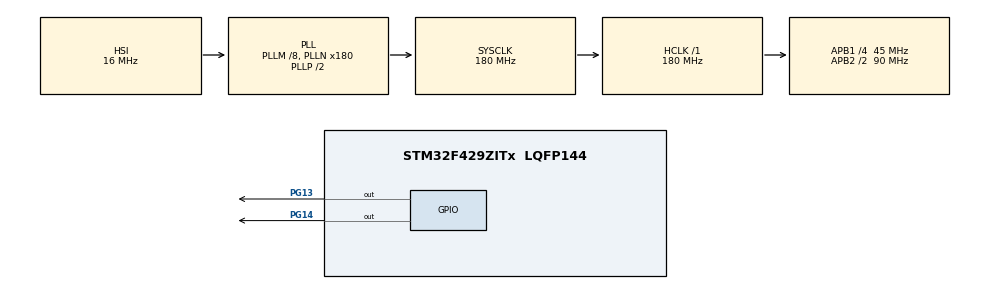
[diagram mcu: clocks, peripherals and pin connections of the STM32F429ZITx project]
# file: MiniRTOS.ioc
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Mcu.Family=STM32F4
Mcu.Name=STM32F429ZITx
Mcu.Package=LQFP144
NVIC.FLASH_IRQn=true\:5\:0\:true\:false\:true\:true\:true\:true
NVIC.PVD_IRQn=true\:5\:0\:true\:false\:true\:true\:true\:true
NVIC.PriorityGroup=NVIC_PRIORITYGROUP_4
NVIC.RCC_IRQn=true\:5\:0\:true\:false\:true\:true\:false\:true
PA13.Mode=Serial_Wire
PA13.Signal=SYS_JTMS-SWDIO
PA14.Mode=Serial_Wire
PA14.Signal=SYS_JTCK-SWCLK
PG13.Signal=GPIO_Output
PG14.Signal=GPIO_Output
ProjectManager.HeapSize=0x200
ProjectManager.StackSize=0x400
ProjectManager.TargetToolchain=STM32CubeIDE
RCC.48MHZClocksFreq_Value=90000000
RCC.AHBFreq_Value=180000000
RCC.APB1CLKDivider=RCC_HCLK_DIV4
RCC.APB1Freq_Value=45000000
RCC.APB1TimFreq_Value=90000000
RCC.APB2CLKDivider=RCC_HCLK_DIV2
RCC.APB2Freq_Value=90000000
RCC.APB2TimFreq_Value=180000000
RCC.CortexFreq_Value=180000000
RCC.HCLKFreq_Value=180000000
RCC.HSE_VALUE=25000000
RCC.HSI_VALUE=16000000
RCC.LSE_VALUE=32768
RCC.PLLM=8
RCC.PLLN=180
RCC.SYSCLKFreq_VALUE=180000000
RCC.SYSCLKSource=RCC_SYSCLKSOURCE_PLLCLK
RCC.VCOOutputFreq_Value=360000000
board=custom

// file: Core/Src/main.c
/* USER CODE BEGIN Header */
/**
  ******************************************************************************
  * @file           : main.c
  * @brief          : Main program body
  ******************************************************************************
  * @attention
  *
  * Copyright (c) 2026 STMicroelectronics.
  * All rights reserved.
  *
  * This software is licensed under terms that can be found in the LICENSE file
  * in the root directory of this software component.
  * If no LICENSE file comes with this software, it is provided AS-IS.
  *
  ******************************************************************************
  */
/* USER CODE END Header */
#include "main.h"

/* USER CODE BEGIN Includes */
#include "application/app.h"
/* USER CODE END Includes */

/* USER CODE BEGIN PV */

/* Stack cho mỗi task (256 words = 1KB mỗi task) */
static uint32_t task1Stack[256];
static uint32_t task2Stack[256];
static uint32_t task3Stack[256];

/* TCB cho mỗi task */
static TCB_t task1TCB;
static TCB_t task2TCB;
static TCB_t task3TCB;

/* USER CODE END PV */

void SystemClock_Config(void);
static void MX_GPIO_Init(void);

int main(void)
{

  /* MCU Configuration--------------------------------------------------------*/

  /* Reset of all peripherals, Initializes the Flash interface and the Systick. */
  HAL_Init();

  /* Configure the system clock */
  SystemClock_Config();

  /* Initialize all configured peripherals */
  MX_GPIO_Init();
  /* USER CODE BEGIN 2 */

  /* ====================================================
   * KHỞi TẠO TDRTOS KERNEL
   *
   * Lưu ý: HAL_Init() được giữ lại để cấu hình clock.
   * Sau khi TDRTOS_Start() được call, SysTick sẽ bị
   * scheduler chiếm (HAL_Delay không dùng được nữa).
   * ==================================================== */

  /* 1. Khởi tạo scheduler */
  TDRTOS_SchedulerInit();

  /* 2. Tạo các tasks */
  TDRTOS_TaskCreate(&task1TCB,
                    Task1Function,
                    NULL,
                    task1Stack,
                    256U,
                    0U,       /* Priority 0 = cao nhất */
                    "Task1");

  TDRTOS_TaskCreate(&task2TCB,
                    Task2Function,
                    NULL,
                    task2Stack,
                    256U,
                    1U,       /* Priority 1 */
                    "Task2");

  TDRTOS_TaskCreate(&task3TCB,
                    Task3Function,
                    NULL,
                    task3Stack,
                    256U,
                    2U,       /* Priority 2 = thấp nhất (trước idle) */
                    "Task3");

  /* 3. �?ăng ký tasks vào scheduler */
  TDRTOS_AddTask(&task1TCB);
  TDRTOS_AddTask(&task2TCB);
  TDRTOS_AddTask(&task3TCB);

  /* 4. Bắt đầu scheduler — HÀM NÀY KHÔNG RETURN */
  TDRTOS_Start();

  /* USER CODE END 2 */

  /* Infinite loop */
  /* USER CODE BEGIN WHILE */
  while (1)
  {
//	  HAL_GPIO_TogglePin(GPIOG, GPIO_PIN_13);
//	  HAL_Delay(1000);
    /* USER CODE END WHILE */

  }
}

void SystemClock_Config(void)
{
  RCC_OscInitTypeDef RCC_OscInitStruct = {0};
  RCC_ClkInitTypeDef RCC_ClkInitStruct = {0};

  /** Configure the main internal regulator output voltage
  */
  __HAL_RCC_PWR_CLK_ENABLE();
  __HAL_PWR_VOLTAGESCALING_CONFIG(PWR_REGULATOR_VOLTAGE_SCALE1);

  /** Initializes the RCC Oscillators according to the specified parameters
  * in the RCC_OscInitTypeDef structure.
  */
  RCC_OscInitStruct.OscillatorType = RCC_OSCILLATORTYPE_HSI;
  RCC_OscInitStruct.HSIState = RCC_HSI_ON;
  RCC_OscInitStruct.HSICalibrationValue = RCC_HSICALIBRATION_DEFAULT;
  RCC_OscInitStruct.PLL.PLLState = RCC_PLL_ON;
  RCC_OscInitStruct.PLL.PLLSource = RCC_PLLSOURCE_HSI;
  RCC_OscInitStruct.PLL.PLLM = 8;
  RCC_OscInitStruct.PLL.PLLN = 180;
  RCC_OscInitStruct.PLL.PLLP = RCC_PLLP_DIV2;
  RCC_OscInitStruct.PLL.PLLQ = 4;
  if (HAL_RCC_OscConfig(&RCC_OscInitStruct) != HAL_OK)
  {
    Error_Handler();
  }

  /** Activate the Over-Drive mode
  */
  if (HAL_PWREx_EnableOverDrive() != HAL_OK)
  {
    Error_Handler();
  }

  /** Initializes the CPU, AHB and APB buses clocks
  */
  RCC_ClkInitStruct.ClockType = RCC_CLOCKTYPE_HCLK|RCC_CLOCKTYPE_SYSCLK
                              |RCC_CLOCKTYPE_PCLK1|RCC_CLOCKTYPE_PCLK2;
  RCC_ClkInitStruct.SYSCLKSource = RCC_SYSCLKSOURCE_PLLCLK;
  RCC_ClkInitStruct.AHBCLKDivider = RCC_SYSCLK_DIV1;
  RCC_ClkInitStruct.APB1CLKDivider = RCC_HCLK_DIV4;
  RCC_ClkInitStruct.APB2CLKDivider = RCC_HCLK_DIV2;

  if (HAL_RCC_ClockConfig(&RCC_ClkInitStruct, FLASH_LATENCY_5) != HAL_OK)
  {
    Error_Handler();
  }
}

static void MX_GPIO_Init(void)
{
  GPIO_InitTypeDef GPIO_InitStruct = {0};

  /* GPIO Ports Clock Enable */
  __HAL_RCC_GPIOA_CLK_ENABLE();
  __HAL_RCC_GPIOG_CLK_ENABLE();

  /*Configure GPIO pin Output Level */
  HAL_GPIO_WritePin(GPIOG, GPIO_PIN_13|GPIO_PIN_14, GPIO_PIN_RESET);

  /*Configure GPIO pins : PG13 PG14 */
  GPIO_InitStruct.Pin = GPIO_PIN_13|GPIO_PIN_14;
  GPIO_InitStruct.Mode = GPIO_MODE_OUTPUT_PP;
  GPIO_InitStruct.Pull = GPIO_NOPULL;
  GPIO_InitStruct.Speed = GPIO_SPEED_FREQ_LOW;
  HAL_GPIO_Init(GPIOG, &GPIO_InitStruct);

/* USER CODE BEGIN MX_GPIO_Init_2 */
  /* Cấu hình PG13, PG14 làm output (LED LD3, LD4 trên Nucleo-F429ZI) */
  GPIO_InitStruct.Pin   = GPIO_PIN_13 | GPIO_PIN_14;
  GPIO_InitStruct.Mode  = GPIO_MODE_OUTPUT_PP;
  GPIO_InitStruct.Pull  = GPIO_NOPULL;
  GPIO_InitStruct.Speed = GPIO_SPEED_FREQ_LOW;
  HAL_GPIO_Init(GPIOG, &GPIO_InitStruct);

  /* Tắt LED ban đầu */
  HAL_GPIO_WritePin(GPIOG, GPIO_PIN_13 | GPIO_PIN_14, GPIO_PIN_RESET);
/* USER CODE END MX_GPIO_Init_2 */
}

void Error_Handler(void)
{
  __disable_irq();
  while (1)
  {
  }
}
